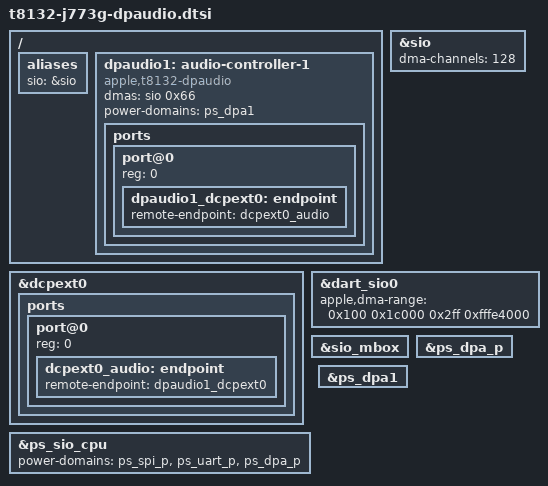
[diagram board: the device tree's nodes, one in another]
// SPDX-License-Identifier: GPL-2.0+ OR MIT
/*
 * Mac mini (M4, J773g) HDMI audio. The ADT gives each display processor its
 * DP audio block ("audio"): dcp = dp-audio0 (SIO DMA channel 0x64, DPA0),
 * dcpext0 = dp-audio1 (0x66, DPA1) and dcpext1 = dp-audio2 (0x68, DPA2), all
 * under DPA_P. On the macOS 27.2 firmware the HDMI port runs from dcpext0,
 * and macOS 27.2 plays HDMI audio through its dcpav-audio-interface, so DPA1
 * is the HDMI port's audio interface; DPA0 and DPA2 stay off.
 *
 * SIO supplies the sample stream. iBoot preloads its firmware; the boot
 * loader reserves it, publishes the boot tables (the T6041 layout: the ADT's
 * map-range, device-type, dmashim and asio-ascwrap-tunables records match it
 * key for key) and then enables the SIO node, which it finds by the alias.
 * Without such a loader DPA1 waits for its DMA channel and nothing else
 * changes.
 */

/ {
	aliases {
		sio = &sio;
	};

	dpaudio1: audio-controller-1 {
		compatible = "apple,t8132-dpaudio", "apple,dpaudio";
		dmas = <&sio 0x66>;
		dma-names = "tx";
		power-domains = <&ps_dpa1>;
		status = "okay";

		ports {
			#address-cells = <1>;
			#size-cells = <0>;

			port@0 {
				reg = <0>;
				dpaudio1_dcpext0: endpoint {
					remote-endpoint = <&dcpext0_audio>;
				};
			};
		};
	};
};

&dcpext0 {
	ports {
		#address-cells = <1>;
		#size-cells = <0>;

		port@0 {
			reg = <0>;
			dcpext0_audio: endpoint {
				remote-endpoint = <&dpaudio1_dcpext0>;
			};
		};
	};
};

/* Channel numbers run up to dp-audio2's 0x68, as on T8140. */
&sio {
	dma-channels = <128>;
};

/* The boot tables sit in the window above the preloaded segments (ADT vm-base, vm-size). */
&dart_sio0 {
	apple,dma-range = <0x100 0x1c000 0x2ff 0xfffe4000>;
	status = "okay";
};

&sio_mbox {
	status = "okay";
};

/*
 * The SIO firmware drives the SPI, UART and DP audio shims, so keep their
 * parents on while it runs, as on T6041 and T8140.
 */
&ps_sio_cpu {
	power-domains = <&ps_spi_p>, <&ps_uart_p>, <&ps_dpa_p>;
	status = "okay";
};

&ps_dpa_p {
	status = "okay";
};

&ps_dpa1 {
	status = "okay";
};
